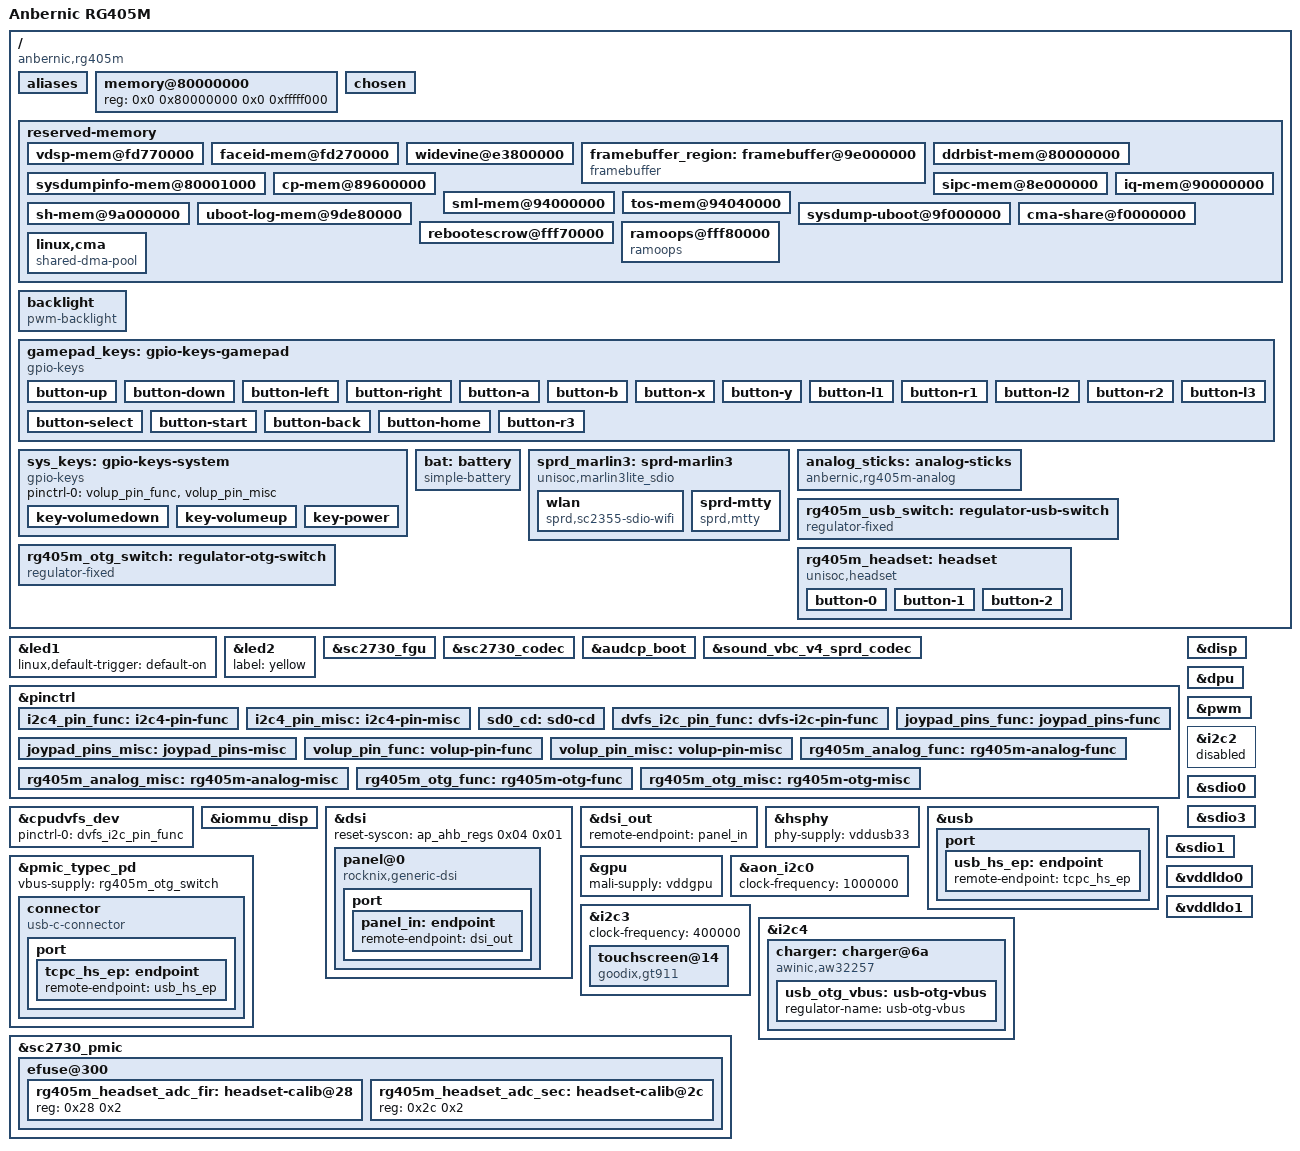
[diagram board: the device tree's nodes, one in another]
// SPDX-License-Identifier: (GPL-2.0 OR MIT)
/* RG405M board data from GammaOS DTBO 1 and stock V1.15; see HARDWARE.md. */

/dts-v1/;

#include <dt-bindings/gpio/gpio.h>
#include <dt-bindings/input/input.h>
#include <dt-bindings/input/gpio-keys.h>
#include <dt-bindings/clock/sprd,ums512-clk.h>
#include <dt-bindings/mfd/sprd,sc2730-regs.h>
#include <dt-bindings/mfd/sprd,sc2730-mask.h>
#include "ums512.dtsi"
#include "sc2730.dtsi"
#include "sprd-sound-fe-be.dtsi"

/ {
	model = "Anbernic RG405M";
	compatible = "anbernic,rg405m", "sprd,ums512";
	sprd,sc-id = "ums512 1h10 1000";

	aliases {
		serial0 = &uart0;
		serial1 = &uart1;
	};

	memory@80000000 {
		device_type = "memory";
		reg = <0x0 0x80000000 0x0 0xfffff000>;
	};

	chosen {
		#address-cells = <2>;
		#size-cells = <2>;
	};

	reserved-memory {
		#address-cells = <2>;
		#size-cells = <2>;
		ranges;
		vdsp-mem@fd770000 {
			reg = <0x0 0xfd770000 0x0 0x2800000>;
			no-map;
		};
		faceid-mem@fd270000 {
			reg = <0x0 0xfd270000 0x0 0x500000>;
			no-map;
		};
		widevine@e3800000 {
			reg = <0x0 0xe3800000 0x0 0xc800000>;
			no-map;
		};
		framebuffer_region: framebuffer@9e000000 {
			compatible = "framebuffer";
			reg = <0 0x9e000000 0 0x9e4000>;
			iommu-addresses = <&dpu 0x9e000000 0x9e4000>;
			no-map;
		};
		ddrbist-mem@80000000 {
			reg = <0x0 0x80000000 0x0 0x1000>;
			no-map;
		};
		sysdumpinfo-mem@80001000 {
			reg = <0x0 0x80001000 0x0 0x1000>;
			no-map;
		};
		cp-mem@89600000 {
			reg = <0x0 0x89600000 0x0 0x4900000>;
			no-map;
		};
		sipc-mem@8e000000 {
			reg = <0x0 0x8e000000 0x0 0x900000>;
			no-map;
		};
		iq-mem@90000000 {
			reg = <0x0 0x90000000 0x0 0x4000000>;
			no-map;
		};
		sml-mem@94000000 {
			reg = <0x0 0x94000000 0x0 0x40000>;
			no-map;
		};
		tos-mem@94040000 {
			reg = <0x0 0x94040000 0x0 0x5fc0000>;
			no-map;
		};
		sh-mem@9a000000 {
			reg = <0x0 0x9a000000 0x0 0x100000>;
			no-map;
		};
		uboot-log-mem@9de80000 {
			reg = <0x0 0x9de80000 0x0 0x80000>;
			no-map;
		};
		sysdump-uboot@9f000000 {
			reg = <0x0 0x9f000000 0x0 0x1000000>;
			no-map;
		};
		cma-share@f0000000 {
			reg = <0x0 0xf0000000 0x0 0x3000000>;
			no-map;
		};
		rebootescrow@fff70000 {
			reg = <0x0 0xfff70000 0x0 0x10000>;
			no-map;
		};
		ramoops@fff80000 {
			reg = <0x0 0xfff80000 0x0 0x40000>;
			compatible = "ramoops";
			record-size = <0x8000>;
			console-size = <0x8000>;
			pmsg-size = <0x8000>;
		};
		linux,cma {
			compatible = "shared-dma-pool";
			size = <0 0x8000000>;
			reusable;
			linux,cma-default;
		};
	};

	backlight: backlight {
		compatible = "pwm-backlight";
		pwms = <&pwm 2 40000>;
		brightness-levels = <0 3 4 5 6 7 8 9 10 11 12 13 14 15 16 17 18 19 20 21 22 23 24 25 26 27 28 29 31 33 35 37 39 41 43 45 46 48 50 52 54 56 58 60 62 64 66 68 70 72 74 76 78 80 82 84 86 88 90 92 94 96 98 100 102 104 106 108 110 112 114 116 118 120 122 124 126 128 130 132 134 136 138 140 142 144 146 148 150 152 154 156 158 160 162 164 166 169 172 175 178 181 184 187 190 193 196 199 202 205 208 211 214 217 220 223 226 229 232 235 238 241 244 247 250 253 256 259 262 265 268 271 274 277 280 283 286 290 294 298 302 306 310 314 318 322 326 330 334 338 342 346 350 354 358 362 366 370 374 378 382 386 390 394 398 402 406 410 414 418 422 426 430 434 438 442 446 451 456 461 466 471 476 481 486 491 496 501 506 511 516 521 526 531 536 541 546 551 556 561 566 571 576 581 586 591 596 601 606 611 616 621 626 631 636 641 646 652 658 664 670 676 682 688 694 700 706 712 718 724 730 736 742 748 754 760 766 772 778 784 790 796 802 808 814 820 826 832 838 844 850 856 862 868 874 880>;
		default-brightness-level = <64>;
	};

	gamepad_keys: gpio-keys-gamepad {
		compatible = "gpio-keys";
		label = "RG405M Buttons";
		pinctrl-names = "default";
		pinctrl-0 = <&joypad_pins_func &joypad_pins_misc>;
		button-up {
			label = "UP";
			linux,code = <BTN_DPAD_UP>;
			gpios = <&ap_gpio 26 GPIO_ACTIVE_LOW>;
			debounce-interval = <2>;
		};
		button-down {
			label = "DOWN";
			linux,code = <BTN_DPAD_DOWN>;
			gpios = <&ap_gpio 25 GPIO_ACTIVE_LOW>;
			debounce-interval = <2>;
		};
		button-left {
			label = "LEFT";
			linux,code = <BTN_DPAD_LEFT>;
			gpios = <&ap_gpio 97 GPIO_ACTIVE_LOW>;
			debounce-interval = <2>;
		};
		button-right {
			label = "RIGHT";
			linux,code = <BTN_DPAD_RIGHT>;
			gpios = <&ap_gpio 86 GPIO_ACTIVE_LOW>;
			debounce-interval = <2>;
		};
		button-a {
			label = "A";
			linux,code = <BTN_EAST>;
			gpios = <&ap_gpio 116 GPIO_ACTIVE_LOW>;
			debounce-interval = <2>;
		};
		button-b {
			label = "B";
			linux,code = <BTN_SOUTH>;
			gpios = <&ap_gpio 112 GPIO_ACTIVE_LOW>;
			debounce-interval = <2>;
		};
		button-x {
			label = "X";
			linux,code = <BTN_NORTH>;
			gpios = <&ap_gpio 88 GPIO_ACTIVE_LOW>;
			debounce-interval = <2>;
		};
		button-y {
			label = "Y";
			linux,code = <BTN_WEST>;
			gpios = <&ap_gpio 113 GPIO_ACTIVE_LOW>;
			debounce-interval = <2>;
		};
		button-l1 {
			label = "L1";
			linux,code = <BTN_TL>;
			gpios = <&ap_gpio 14 GPIO_ACTIVE_LOW>;
			debounce-interval = <2>;
		};
		button-r1 {
			label = "R1";
			linux,code = <BTN_TR>;
			gpios = <&ap_gpio 1 GPIO_ACTIVE_LOW>;
			debounce-interval = <2>;
		};
		button-l2 {
			label = "L2";
			linux,code = <BTN_TL2>;
			gpios = <&ap_gpio 3 GPIO_ACTIVE_LOW>;
			debounce-interval = <2>;
		};
		button-r2 {
			label = "R2";
			linux,code = <BTN_TR2>;
			gpios = <&ap_gpio 2 GPIO_ACTIVE_LOW>;
			debounce-interval = <2>;
		};
		button-select {
			label = "SELECT";
			linux,code = <BTN_SELECT>;
			gpios = <&ap_gpio 55 GPIO_ACTIVE_LOW>;
			debounce-interval = <2>;
		};
		button-start {
			label = "START";
			linux,code = <BTN_START>;
			gpios = <&ap_gpio 87 GPIO_ACTIVE_LOW>;
			debounce-interval = <2>;
		};
		button-back {
			label = "BACK";
			linux,code = <BTN_MODE>;
			gpios = <&ap_gpio 124 GPIO_ACTIVE_LOW>;
			debounce-interval = <2>;
		};
		button-home {
			label = "HOME";
			linux,code = <KEY_F10>;
			gpios = <&ap_gpio 126 GPIO_ACTIVE_LOW>;
			debounce-interval = <2>;
		};
		button-l3 {
			label = "L3";
			linux,code = <BTN_THUMBL>;
			gpios = <&ap_gpio 20 GPIO_ACTIVE_LOW>;
			debounce-interval = <2>;
		};
		button-r3 {
			label = "R3";
			linux,code = <BTN_THUMBR>;
			gpios = <&ap_gpio 23 GPIO_ACTIVE_LOW>;
			debounce-interval = <2>;
		};
	};

	sys_keys: gpio-keys-system {
		compatible = "gpio-keys";
		pinctrl-names = "default";
		pinctrl-0 = <&volup_pin_func &volup_pin_misc>;

		key-volumedown {
			label = "Volume Down Key";
			linux,code = <KEY_VOLUMEDOWN>;
			gpios = <&pmic_eic 4 GPIO_ACTIVE_HIGH>;
			debounce-interval = <2>;
		};
		key-volumeup {
			label = "Volume Up Key";
			linux,code = <KEY_VOLUMEUP>;
			gpios = <&ap_gpio 30 GPIO_ACTIVE_LOW>;
			debounce-interval = <2>;
		};
		key-power {
			label = "Power Key";
			linux,code = <KEY_POWER>;
			gpios = <&pmic_eic 1 GPIO_ACTIVE_LOW>;
			debounce-interval = <2>;
			wakeup-source;
		};
	};

	bat: battery {
		compatible = "simple-battery";
		charge-full-design-microamp-hours = <0x401640>;
		charge-term-current-microamp = <0x1d4c0>;
		constant-charge-voltage-max-microvolt = <0x419ce0>;
		factory-internal-resistance-micro-ohms = <0x1fbd0>;
		voltage-min-design-microvolt = <0x340850>;
		ocv-capacity-celsius = <0x19>;
		ocv-capacity-table-0 = <0x417da0 0x64 0x3fd7c0 0x5f 0x3ed5f0 0x5a 0x3dbcb0 0x55 0x3cde08 0x50 0x3c0730 0x4b 0x3b3828 0x46 0x3a4dc8 0x41 0x399a18 0x3c 0x38e668 0x37 0x383a88 0x32 0x37c940 0x2d 0x3786d8 0x28 0x375028 0x23 0x370dc0 0x1e 0x36c388 0x19 0x365df8 0x14 0x35e8c8 0xf 0x354c88 0xa 0x349cc0 0x5 0x33e140 0x0>;
		resistance-temp-table = <0x2d 0x7d 0x19 0x7d 0xa 0xa0 0x0 0xc8 0xfffffff6 0x192 0xffffffec 0x20b>;
		voltage-temp-table = <1095000 (-200)>, <986000 (-150)>, <878000 (-100)>, <775000 (-50)>, <678000 (0)>, <590000 (50)>, <510000 (100)>, <440000 (150)>, <378000 (200)>, <324000 (250)>, <278000 (300)>, <238000 (350)>, <204000 (400)>, <175000 (450)>, <150000 (500)>, <129000 (550)>, <111000 (600)>, <96000 (650)>;
		operating-range-celsius = <0 45>;
	};

};

&led1 {
	linux,default-trigger = "default-on";
};

&led2 {
	label = "yellow";
};

&sc2730_fgu {
	status = "okay";
	monitored-battery = <&bat>;
	power-supplies = <&charger>;
	sprd,calib-resistance-micro-ohms = <10000>;
};

&sc2730_codec {
	status = "okay";
	sprd,syscon-pmu-apb = <&pmu_apb_regs>;
	hp-use-inter-pa = <1>;
	fixed-sample-rate = <48000 48000 48000>;
	digital-codec = <&sprd_audio_codec_dig>;
};

&audcp_boot {
	status = "okay";
};

&sound_vbc_v4_sprd_codec {
	sprd-audio-card,name = "RG405M";
	status = "okay";
	/* Keep the stock headphone/microphone routes inherited from the dtsi. */
	sprd,spk-ext-pa-info = <0 0 0 0>;
	sprd,spk-ext-pa-gpio = <&ap_gpio 9 1>;
};

&pinctrl {
	i2c4_pin_func: i2c4-pin-func {
		pins = "UMS512_SIMCLK2", "UMS512_SIMDA2";
		function = "func2";
	};

	i2c4_pin_misc: i2c4-pin-misc {
		pins = "UMS512_SIMCLK2_MISC", "UMS512_SIMDA2_MISC";
		
		bias-pull-up = <4700>;
	};

    sd0_cd: sd0-cd {
        pins = "UMS512_RFFE1_SDA";
        function = "func4";
    };

	dvfs_i2c_pin_func: dvfs-i2c-pin-func {
		pins = "UMS512_SDA3", "UMS512_SCL3";
		function = "func1";
	};

	joypad_pins_func: joypad_pins-func {
		pins = "UMS512_RFSDA0", "UMS512_RFSCK0", "UMS512_RFSEN0", "UMS512_RFSEN1", "UMS512_RFCTL1", "UMS512_RFCTL4", "UMS512_RFCTL6", "UMS512_RFCTL7", "UMS512_SPI2_CLK", "UMS512_MEMS_MIC_DATA1", "UMS512_IIS3DI", "UMS512_IIS3DO", "UMS512_KEYIN0", "UMS512_KEYIN2";
		function = "func4";
	};
	joypad_pins_misc: joypad_pins-misc {
		pins = "UMS512_RFSDA0_MISC", "UMS512_RFSCK0_MISC", "UMS512_RFSEN0_MISC", "UMS512_RFSEN1_MISC", "UMS512_RFCTL1_MISC", "UMS512_RFCTL4_MISC", "UMS512_RFCTL6_MISC", "UMS512_RFCTL7_MISC", "UMS512_SPI2_CLK_MISC", "UMS512_MEMS_MIC_DATA1_MISC", "UMS512_IIS3DI_MISC", "UMS512_IIS3DO_MISC", "UMS512_KEYIN0_MISC", "UMS512_KEYIN2_MISC";
		input-enable;
		bias-pull-up = <20000>;
	};

	volup_pin_func: volup-pin-func {
		pins = "UMS512_RFCTL11";
		function = "func4";
	};

	volup_pin_misc: volup-pin-misc {
		pins = "UMS512_RFCTL11_MISC";
		input-enable;
		bias-pull-up = <20000>;
	};

};

&cpudvfs_dev {
	pinctrl-names = "default";
	pinctrl-0 = <&dvfs_i2c_pin_func>;
};

&iommu_disp {
	status = "okay";
};

&disp {
	status = "okay";
};

&dpu {
	status = "okay";
	memory-region = <&framebuffer_region>;
	reset-syscon = <&ap_ahb_regs 0x04 0x02>;
};

&pwm {
	status = "okay";
};

&dsi {
	status = "okay";
	reset-syscon = <&ap_ahb_regs 0x04 0x01>;

	#address-cells = <1>;
	#size-cells = <0>;

	panel@0 {
		compatible = "rocknix,generic-dsi";
		reg = <0>;
		status = "okay";
		reset-gpios = <&ap_gpio 50 GPIO_ACTIVE_LOW>;
		backlight = <&backlight>;
		panel_description =
			"G lanes=2 format=rgb888 size=109,62 flags=3 hs_rate=368000000 lp_rate=20000000 delays=5,50,120,200,20",
			"M clock=25600 horizontal=480,54,50,50 vertical=640,10,13,10 default=1",
			"I seq=ff7701000013",
			"I seq=ef08",
			"I seq=ff7701000010",
			"I seq=c04f03",
			"I seq=c10c02",
			"I seq=c21006",
			"I seq=c704",
			"I seq=cc38",
			"I seq=b040161d0e12060c0a09250003003f3f1c",
			"I seq=b140161e0e11060c0809260015003f3f1c",
			"I seq=ff7701000011",
			"I seq=b04d",
			"I seq=b135",
			"I seq=b207",
			"I seq=b380",
			"I seq=b547",
			"I seq=b785",
			"I seq=b820",
			"I seq=b910",
			"I seq=bc03",
			"I seq=c089",
			"I seq=c178",
			"I seq=c278",
			"I seq=d088",
			"I seq=e0000002",
			"I seq=e10400000005000000002020",
			"I seq=e200000000000000000000000000",
			"I seq=e300003300",
			"I seq=e42200",
			"I seq=e5045ca0a0065ca0a00000000000000000",
			"I seq=e600003300",
			"I seq=e72200",
			"I seq=e8055ca0a0075ca0a00000000000000000",
			"I seq=eb02004040000000",
			"I seq=ec0000",
			"I seq=edfa450bffffffffffffffffffffb054af",
			"I seq=ef080808453f54",
			"I seq=ff7701000000",
			"I seq=3617",
			"I seq=3a77";
		port {
			panel_in: endpoint { remote-endpoint = <&dsi_out>; };
		};
	};
};

&dsi_out {
	remote-endpoint = <&panel_in>;
};

&hsphy {
	status = "okay";
	phy-supply = <&vddusb33>;
};

&usb {
	status = "okay";
	dr_mode = "otg";
	usb-role-switch;
	role-switch-default-mode = "peripheral";

	port {
		usb_hs_ep: endpoint {
			remote-endpoint = <&tcpc_hs_ep>;
		};
	};
};

&pmic_typec_pd {
	status = "okay";
	vbus-supply = <&rg405m_otg_switch>;

	connector {
		compatible = "usb-c-connector";
		label = "USB-C";
		power-role = "dual";
		data-role = "dual";
		try-power-role = "sink";
		pd-disable;
		typec-power-opmode = "default";

		port {
			tcpc_hs_ep: endpoint {
				remote-endpoint = <&usb_hs_ep>;
			};
		};
	};
};

&gpu {
	mali-supply = <&vddgpu>;
	status = "okay";
};

&aon_i2c0 {
	status = "okay";
	clock-frequency = <1000000>;
};

&cpudvfs_dev {
	status = "okay";
};

&i2c2 {
	status = "disabled";
};

&i2c3 {
	status = "okay";
	clock-frequency = <400000>;
	#address-cells = <1>;
	#size-cells = <0>;

	touchscreen@14 {
		compatible = "goodix,gt911";
		reg = <0x14>;
		AVDD28-supply = <&vddldo1>;
		VDDIO-supply = <&vddldo1>;
		irq-gpios = <&ap_gpio 144 GPIO_ACTIVE_HIGH>;
		reset-gpios = <&ap_gpio 145 GPIO_ACTIVE_HIGH>;
		touchscreen-size-x = <480>;
		touchscreen-size-y = <640>;
	};
};

&i2c4 {
	status = "okay";
	clock-frequency = <400000>;
	pinctrl-names = "default";
	pinctrl-0 = <&i2c4_pin_func &i2c4_pin_misc>;
	#address-cells = <1>;
	#size-cells = <0>;

	charger: charger@6a {
		compatible = "awinic,aw32257";
		status = "okay";
		reg = <0x6a>;
		monitored-battery = <&bat>;
		fuel-gauge = <&sc2730_fgu>;
		ti,current-limit = <500>;
		ti,weak-battery-voltage = <3400>;
		ti,battery-regulation-voltage = <4200>;
		/* AW32257 REG04 code 0: 16368 uV / 33 mOhm. */
		ti,charge-current = <496>;
		/* Code 1 is 124 mA, above the stock 120 mA termination target. */
		ti,termination-current = <62>;
		ti,resistor-sense = <33>;

		usb_otg_vbus: usb-otg-vbus {
			regulator-name = "usb-otg-vbus";
		};
	};
};

&sdio0 {
	status = "okay";
	vmmc-supply = <&vddsdcore>;
	vqmmc-supply = <&vddsdio>;
	cd-gpios = <&eic_sync 19 GPIO_ACTIVE_LOW>;
	bus-width = <4>;
	sprd,phy-delay-sd-uhs-sdr104 = <0x7f 0x73 0x72 0x72>;
	sprd,phy-delay-sd-uhs-sdr50 = <0x6e 0x7f 0x01 0x01>;
	sprd,phy-delay-sd-highspeed = <0x7f 0x1a 0x9a 0x9a>;
	sprd,phy-delay-legacy = <0x7f 0x1a 0x9a 0x9a>;
	sd-uhs-sdr104;
	sd-uhs-sdr50;
	no-sdio;
	no-mmc;
};

&sdio3 {
	status = "okay";
	vmmc-supply = <&vddemmccore>;
	bus-width = <8>;
	voltage-ranges = <3000 3000>;
	non-removable;
	cap-mmc-hw-reset;
	sprd,phy-delay-mmc-hs400es = <0x40 0x7f 0x2d 0x2d>;
	sprd,phy-delay-mmc-hs400 = <0x3f 0xdf 0x2f 0x2f>;
	sprd,phy-delay-mmc-hs200 = <0x7f 0xde 0xd4 0xd4>;
	sprd,phy-delay-mmc-ddr52 = <0x3e 0x37 0x24 0x24>;
	sprd,phy-delay-mmc-highspeed = <0x60 0xb7 0x34 0x34>;
	mmc-hs400-enhanced-strobe;
	mmc-hs400-1_8v;
	mmc-hs200-1_8v;
	mmc-ddr-1_8v;
	no-sdio;
	no-sd;
};

&sdio1 {
	status = "okay";
	bus-width = <4>;
	sprd,phy-delay-sd-uhs-sdr104 = <0x7f 0x76 0x69 0x69>;
	sprd,phy-delay-sd-uhs-sdr50 = <0x7f 0xf7 0xf5 0xf5>;
	sd-uhs-sdr104;
	sd-uhs-sdr50;
	no-sd;
	no-mmc;
};

/ {
	sprd_marlin3: sprd-marlin3 {
		compatible = "unisoc,marlin3lite_sdio";
		status = "okay";

		enable-gpios = <&ap_gpio 143 GPIO_ACTIVE_LOW>;
		reset-gpios = <&ap_gpio 95 GPIO_ACTIVE_LOW>;
		m2-wakeup-ap-gpios = <&ap_gpio 32 GPIO_ACTIVE_LOW>;
		m2-to-ap-irq-gpios = <&ap_gpio 94 GPIO_ACTIVE_LOW>;
		adma-tx;
		adma-rx;

		clock-names = "clk_32k", "source", "enable";
		clocks = <&aon_clk CLK_AUX0>, <&ext_32k>,
			 <&aonapb_gate CLK_AUX0_EB>;

		extcon = <&sdio1>;
		sdhci-name = <&sdio1>;

		sprd,btwf-file-name = "/lib/firmware/wcnmodem.bin";
		sprd,gnss-file-name = "/lib/firmware/gnssmodem.bin";

		avdd12-supply = <&vddwcn>;
		avdd33-supply = <&vddwifipa>;
		dcxo18-supply = <&vddsim2>;

		avdd12-parent-bound-chip = <REG_ANA_SLP_DCDC_PD_CTRL MASK_ANA_SLP_DCDCGEN1_PD_EN 0x0 MASK_ANA_SLP_DCDCGEN1_PD_EN>;
		avdd12-bound-wbreq = <REG_ANA_LDO_XTL_EN10 MASK_ANA_LDO_VDDWCN_EXT_XTL3_EN 0x0 MASK_ANA_LDO_VDDWCN_EXT_XTL3_EN>;
		avdd33-bound-wbreq = <REG_ANA_LDO_XTL_EN11 MASK_ANA_LDO_VDDWIFIPA_EXT_XTL3_EN 0x0 MASK_ANA_LDO_VDDWIFIPA_EXT_XTL3_EN>;

		wlan {
			compatible = "sprd,sc2355-sdio-wifi";
			nvmem-cells = <&uid_start>, <&uid_end>;
			nvmem-cell-names = "uid-start", "uid-end";
		};

		sprd-mtty {
			compatible = "sprd,mtty";
			nvmem-cells = <&uid_start>, <&uid_end>;
			nvmem-cell-names = "uid-start", "uid-end";
		};
	};
};

/* Stock RG405M keeps LDO0 always on (unlisted consumer, display power); do not let mainline disable it. */
&vddldo0 { regulator-always-on; regulator-boot-on; };

&vddldo1 { regulator-min-microvolt = <3300000>; regulator-max-microvolt = <3300000>; };

/ {
	analog_sticks: analog-sticks {
		compatible = "anbernic,rg405m-analog";
		invert-absx;
		invert-absy;
		pinctrl-names = "default";
		pinctrl-0 = <&rg405m_analog_func &rg405m_analog_misc>;
		io-channels = <&pmic_adc 2>;
		io-channel-names = "joypad_adc";
		vdd-supply = <&vddldo1>;
		amux-a-gpios = <&ap_gpio 36 GPIO_ACTIVE_HIGH>;
		amux-b-gpios = <&ap_gpio 37 GPIO_ACTIVE_HIGH>;
		amux-en-gpios = <&ap_gpio 15 GPIO_ACTIVE_LOW>;
		power-gpios = <&ap_gpio 19 GPIO_ACTIVE_HIGH>,
			      <&ap_gpio 21 GPIO_ACTIVE_HIGH>,
			      <&ap_gpio 22 GPIO_ACTIVE_HIGH>,
			      <&ap_gpio 24 GPIO_ACTIVE_HIGH>;
		status = "okay";
	};

	/* Vendor sprd_hostphy_set drives GPIO33/96 HIGH only in host mode. */
	rg405m_usb_switch: regulator-usb-switch {
		compatible = "regulator-fixed";
		regulator-name = "rg405m-usb-switch";
		regulator-min-microvolt = <5000000>;
		regulator-max-microvolt = <5000000>;
		vin-supply = <&usb_otg_vbus>;
		gpio = <&ap_gpio 33 GPIO_ACTIVE_HIGH>;
		enable-active-high;
	};
	rg405m_otg_switch: regulator-otg-switch {
		compatible = "regulator-fixed";
		regulator-name = "rg405m-otg-switch";
		regulator-min-microvolt = <5000000>;
		regulator-max-microvolt = <5000000>;
		vin-supply = <&rg405m_usb_switch>;
		pinctrl-names = "default";
		pinctrl-0 = <&rg405m_otg_func &rg405m_otg_misc>;
		gpio = <&ap_gpio 96 GPIO_ACTIVE_HIGH>;
		enable-active-high;
	};
};

&pinctrl {
	rg405m_analog_func: rg405m-analog-func {
		pins = "UMS512_RFFE0_SCK", "UMS512_RFFE0_SDA", "UMS512_RFFE1_SCK",
		       "UMS512_RFCTL0", "UMS512_RFCTL2", "UMS512_RFCTL3", "UMS512_RFCTL5";
		function = "func4";
	};
	rg405m_analog_misc: rg405m-analog-misc {
		pins = "UMS512_RFFE0_SCK_MISC", "UMS512_RFFE0_SDA_MISC", "UMS512_RFFE1_SCK_MISC",
		       "UMS512_RFCTL0_MISC", "UMS512_RFCTL2_MISC", "UMS512_RFCTL3_MISC", "UMS512_RFCTL5_MISC";
		bias-disable;
	};
	rg405m_otg_func: rg405m-otg-func {
		pins = "UMS512_MEMS_MIC_CLK1";
		function = "func4";
	};
	rg405m_otg_misc: rg405m-otg-misc {
		pins = "UMS512_MEMS_MIC_CLK1_MISC";
		bias-disable;
	};
};


/ {
	rg405m_headset: headset {
		compatible = "unisoc,headset";
		status = "okay";
		io-channels = <&pmic_adc 20>;
		io-channel-names = "headmic_in_little";
		gpios = <&pmic_eic 6 GPIO_ACTIVE_HIGH>;
		gpio-names = "aud_int_all";
		sprd,debounce-interval = <10>;
		sprd,jack-type = <1>;
		sprd,irq-threshold-button = <4>;
		sprd,3pole-adc-threshold = <2950>;
		sprd,half-adc-gnd = <100>;
		sprd,adc-gnd = <328>;
		sprd,coefficient = <0xd7f28>;
		sprd,spk-route-hp;
		nvmem-cells = <&rg405m_headset_adc_fir>, <&rg405m_headset_adc_sec>;
		nvmem-cell-names = "hp_adc_fir_calib", "hp_adc_sec_calib";
		button-0 { adc-min = <0>; adc-max = <480>; linux,code = <KEY_MEDIA>; };
		button-1 { adc-min = <481>; adc-max = <990>; linux,code = <KEY_VOLUMEUP>; };
		button-2 { adc-min = <991>; adc-max = <2500>; linux,code = <KEY_VOLUMEDOWN>; };
	};
};

&sc2730_pmic {
	efuse@300 {
		rg405m_headset_adc_fir: headset-calib@28 { reg = <0x28 0x2>; };
		rg405m_headset_adc_sec: headset-calib@2c { reg = <0x2c 0x2>; };
	};
};

&sound_vbc_v4_sprd_codec {
	sprd-audio-card,headset = <&rg405m_headset>;
};
